# D1H.pdf register map
Vendor: Allwinner; Series: D1H.pdf; File version: 0.1
CPU: XuanTie C906 RISC-V CPU 0, little endian, MPU, FPU, double-precision FPU, 0 interrupt priority bits
Registers are 32-bit, read-write, reset 0x0 unless marked. A register's access mark holds for its fields unless they carry their own. Offsets are from the block's base; [hi:lo] are bit positions.

## GPADC
Base 0x02009000
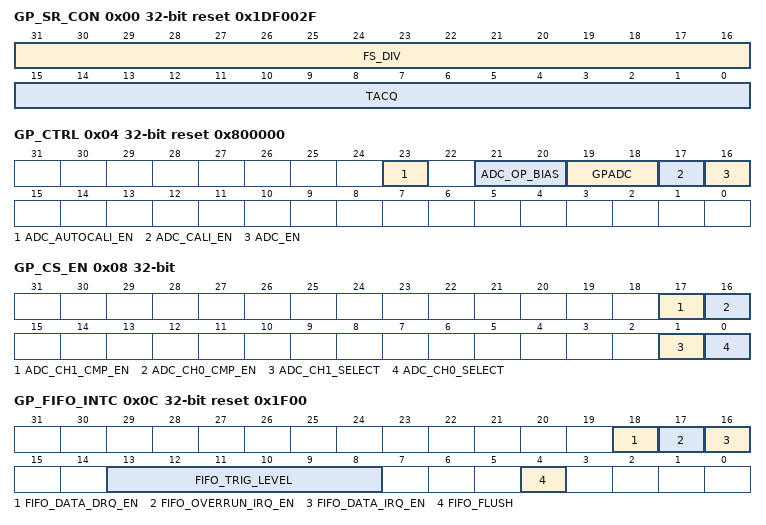
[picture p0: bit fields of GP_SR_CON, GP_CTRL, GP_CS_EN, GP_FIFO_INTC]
0x00 GP_SR_CON reset 0x1DF002F — GPADC Sample Rate Configure Register
  [31:16] FS_DIV — ADC sample frequency divider CLK_IN/(n+1) Default value: 50K
  [15:0] TACQ — ADC acquire time (n+1)/CLK_IN Default value: 2 us
0x04 GP_CTRL reset 0x800000 — GPADC Control Register
  [23] ADC_AUTOCALI_EN — ADC Auto Calibration
  [21:20] ADC_OP_BIAS — ADC OP Bias Adjust the bandwidth of the ADC amplifier
  [19:18] GPADC — Work Mode 00: Single conversion mode 01: Reserved 10: Continuous conversion mode 11: Burst conversion mode
    0=Single conversion mode; 2=Continuous conversion mode; 3=Burst conversion mode
  [17] ADC_CALI_EN — ADC Calibration 1: Start Calibration, it is cleared to 0 after calibration
    1=Start Calibration, it is cleared to 0 after calibration
  [16] ADC_EN — ADC Function Enable Before the bit is enabled, configure ADC parameters including the work mode and channel number, etc. 0: Disable 1: Enable
    0=Disable; 1=Enable
0x08 GP_CS_EN — GPADC Compare and Select Enable Register
  [all] fields
    0=Disable; 1=Enable
  [17] ADC_CH1_CMP_EN — Channel 1 Compare Enable 0: Disable 1: Enable
  [16] ADC_CH0_CMP_EN — Channel 0 Compare Enable 0: Disable 1: Enable
  [1] ADC_CH1_SELECT — Analog Input Channel 1 Select 0: Disable 1: Enable
  [0] ADC_CH0_SELECT — Analog Input Channel 0 Select 0: Disable 1: Enable
0x0C GP_FIFO_INTC reset 0x1F00 — GPADC FIFO Interrupt Control Register
  [18] FIFO_DATA_DRQ_EN — ADC FIFO Date DRQ Enable 0: Disable 1: Enable
    0=Disable; 1=Enable
  [17] FIFO_OVERRUN_IRQ_EN — ADC FIFO Overrun IRQ Enable 0: Disable 1: Enable
    0=Disable; 1=Enable
  [16] FIFO_DATA_IRQ_EN — ADC FIFO Data Available IRQ Enable 0: Disable 1: Enable
    0=Disable; 1=Enable
  [13:8] FIFO_TRIG_LEVEL — Interrupt trigger level for ADC Trigger Level = TXTL + 1
  [4] FIFO_FLUSH — ADC FIFO Flush Write ‘1’ to flush TX FIFO, clear automatically to ‘0’.
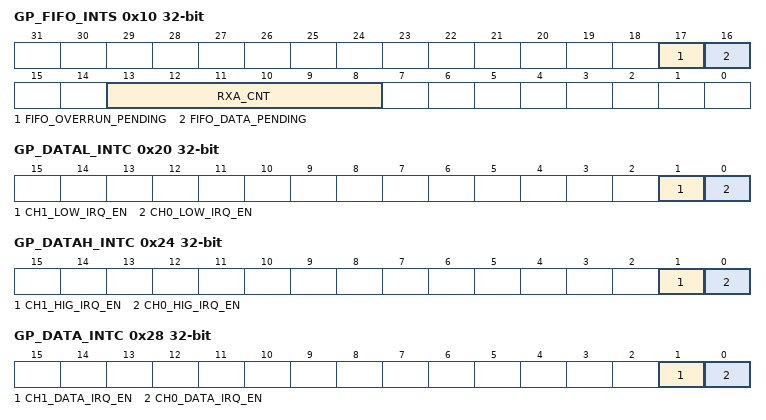
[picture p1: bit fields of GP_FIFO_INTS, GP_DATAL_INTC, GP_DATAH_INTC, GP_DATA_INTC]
0x10 GP_FIFO_INTS — GPADC FIFO Interrupt Status Register
  [17] FIFO_OVERRUN_PENDING write-1-clears — ADC FIFO Overrun IRQ Pending 0: No Pending IRQ 1: FIFO Overrun Pending IRQ Write ‘1’ to clear this interrupt or automatically clear if the interrupt condition fails.
    0=No Pending IRQ; 1=FIFO (FIFO Overrun Pending IRQ Write ‘1’ to clear this interrupt or automatically clear if the interrupt condition fails.)
  [16] FIFO_DATA_PENDING write-1-clears — ADC FIFO Data Available Pending Bit 0: NO Pending IRQ 1: FIFO Available Pending IRQ Write ‘1’ to clear this interrupt or automatically clear if the interrupt condition fails.
    0=NO Pending IRQ; 1=FIFO (FIFO Available Pending IRQ Write ‘1’ to clear this interrupt or automatically clear if the interrupt condition fails.)
  [13:8] RXA_CNT ro — ADC FIFO available sample word counter
0x14 GP_FIFO_DATA — GPADC FIFO Data Register
  [11:0] GP_FIFO_DATA ro — GPADC Data in FIFO
0x18 GP_CDATA — GPADC Calibration Data Register
  [11:0] GP_CDATA — GPADC Calibration Data
0x20 GP_DATAL_INTC — GPADC Data Low Interrupt Configure Register
  [1] CH1_LOW_IRQ_EN — Channel 1 Voltage Low Available Interrupt Enable 0: Disable 1: Enable
    0=Disable; 1=Enable
  [0] CH0_LOW_IRQ_EN — Channel 0 Voltage Low Available Interrupt Enable 0: Disable 1: Enable
    0=Disable; 1=Enable
0x24 GP_DATAH_INTC — GPADC Data High Interrupt Configure Register
  [1] CH1_HIG_IRQ_EN — Channel 1 Voltage High Available Interrupt Enable 0: Disable 1: Enable
    0=Disable; 1=Enable
  [0] CH0_HIG_IRQ_EN — Channel 0 Voltage High Available Interrupt Enable 0: Disable 1: Enable
    0=Disable; 1=Enable
0x28 GP_DATA_INTC — GPADC Data Interrupt Configure Register
  [1] CH1_DATA_IRQ_EN — 0: Disable 1: Enable
    0=Disable; 1=Enable
  [0] CH0_DATA_IRQ_EN — 0: Disable 1: Enable
    0=Disable; 1=Enable
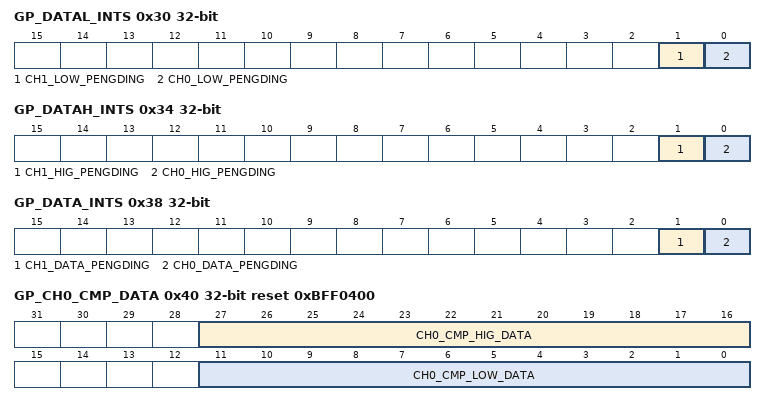
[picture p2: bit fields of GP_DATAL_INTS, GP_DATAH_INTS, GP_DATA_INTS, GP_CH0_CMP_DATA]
0x30 GP_DATAL_INTS — GPADC Data Low Interrupt Status Register
  [1] CH1_LOW_PENGDING write-1-clears — Channel 1 Voltage Low Available Interrupt Status 0: NO Pending IRQ 1: Channel 1 Voltage Low Available Pending IRQ Write ‘1’ to clear this interrupt or automatically clear if the interrupt condition fails.
    0=NO Pending IRQ; 1=Channel 1 Voltage Low Available Pending IRQ Write ‘1’ to clear this interrupt or automatically clear if the interrupt condition fails
  [0] CH0_LOW_PENGDING write-1-clears — Channel 0 Voltage Low Available Interrupt Status 0: NO Pending IRQ 1: Channel 0 Voltage Low Available Pending IRQ Write ‘1’ to clear this interrupt or automatically clear if the interrupt condition fails.
    0=NO Pending IRQ; 1=Channel 0 Voltage Low Available Pending IRQ Write ‘1’ to clear this interrupt or automatically clear if the interrupt condition fails
0x34 GP_DATAH_INTS — GPADC Data High Interrupt Status Register
  [1] CH1_HIG_PENGDING write-1-clears — 0: No Pending IRQ 1: Channel 1 Voltage High Available Pending IRQ Write ‘1’ to clear this interrupt or automatically clear if the interrupt condition fails.
    0=No Pending IRQ; 1=Channel 1 Voltage High Available Pending IRQ Write ‘1’ to clear this interrupt or automatically clear if the interrupt condition fails
  [0] CH0_HIG_PENGDING write-1-clears — 0: No Pending IRQ 1: Channel 0 Voltage High Available Pending IRQ Write ‘1’ to clear this interrupt or automatically clear if the interrupt condition fails.
    0=No Pending IRQ; 1=Channel 0 Voltage High Available Pending IRQ Write ‘1’ to clear this interrupt or automatically clear if the interrupt condition fails
0x38 GP_DATA_INTS — GPADC Data Interrupt Status Register
  [1] CH1_DATA_PENGDING write-1-clears — Channel 1 Data Available Interrupt Status 0: No Pending IRQ 1: Channel 1 Data Available Pending IRQ Write ‘1’ to clear this interrupt or automatically clear if the interrupt condition fails.
    0=No Pending IRQ; 1=Channel 1 Data Available Pending IRQ Write ‘1’ to clear this interrupt or automatically clear if the interrupt condition fails
  [0] CH0_DATA_PENGDING write-1-clears — Channel 0 Data Available Interrupt Status 0: No Pending IRQ 1: Channel 0 Data Available Pending IRQ Write ‘1’ to clear this interrupt or automatically clear if the interrupt condition fails.
    0=No Pending IRQ; 1=Channel 0 Data Available Pending IRQ Write ‘1’ to clear this interrupt or automatically clear if the interrupt condition fails
0x40 GP_CH0_CMP_DATA reset 0xBFF0400 — GPADC CH0 Compare Data Register
  [27:16] CH0_CMP_HIG_DATA — Channel 0 Voltage High Value
  [11:0] CH0_CMP_LOW_DATA — Channel 0 Voltage Low Value
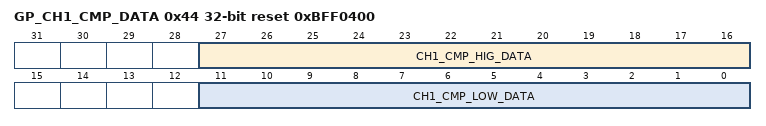
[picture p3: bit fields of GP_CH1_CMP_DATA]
0x44 GP_CH1_CMP_DATA reset 0xBFF0400 — GPADC CH1 Compare Data Register
  [27:16] CH1_CMP_HIG_DATA — Channel 1 Voltage High Value
  [11:0] CH1_CMP_LOW_DATA — Channel 1 Voltage Low Value
0x80 GP_CH0_DATA — GPADC CH0 Data Register
  [11:0] GP_CH0_DATA ro — Channel 0 Data
0x84 GP_CH1_DATA — GPADC CH1 Data Register
  [11:0] GP_CH1_DATA ro — Channel 1 Data
